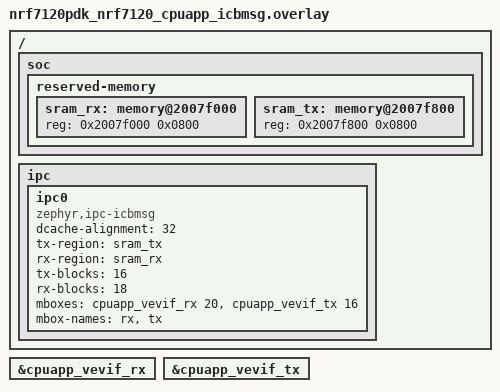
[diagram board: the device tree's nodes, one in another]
/*
 * Copyright (c) 2025 Nordic Semiconductor ASA
 *
 * SPDX-License-Identifier: LicenseRef-Nordic-5-Clause
 */

/ {
	soc {
		reserved-memory {
			#address-cells = <1>;
			#size-cells = <1>;

			sram_rx: memory@2007f000 {
				reg = <0x2007f000 0x0800>;
			};

			sram_tx: memory@2007f800 {
				reg = <0x2007f800 0x0800>;
			};
		};
	};

	ipc {
		ipc0: ipc0 {
			compatible = "zephyr,ipc-icbmsg";
			dcache-alignment = <32>;
			tx-region = <&sram_tx>;
			rx-region = <&sram_rx>;
			tx-blocks = <16>;
			rx-blocks = <18>;
			mboxes = <&cpuapp_vevif_rx 20>, <&cpuapp_vevif_tx 16>;
			mbox-names = "rx", "tx";
			status = "okay";
		};
	};
};

&cpuapp_vevif_rx {
	status = "okay";
};

&cpuapp_vevif_tx {
	status = "okay";
};
